# PRU_ICSS_PRU_CTRL register map
Vendor: Texas Instruments
Peripheral module from a debugger description file (folder am437x).
Registers are 32-bit, access per field, no defined reset value unless marked. A register's access mark holds for its fields unless they carry their own. Offsets are as the file gives them; lines under a group give offsets from that group; [hi:lo] are bit positions; {n}, {i} and the like mark numbered series; 'fields as' and 'values as' point back to an identical list; <NAME> marks a mode.

## PRU_ICSS_PRU_CTRL
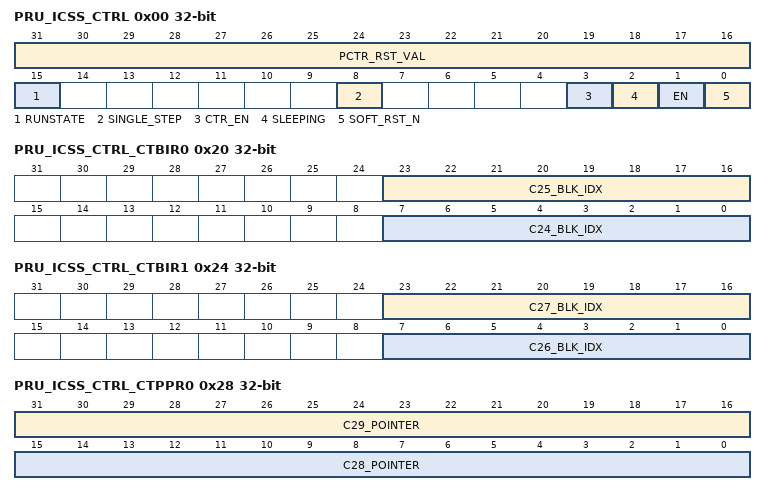
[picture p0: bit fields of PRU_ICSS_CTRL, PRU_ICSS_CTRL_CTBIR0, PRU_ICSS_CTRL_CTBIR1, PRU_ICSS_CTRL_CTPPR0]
0x00 PRU_ICSS_CTRL — CONTROL REGISTER
  [31:16] PCTR_RST_VAL rw — Program Counter Reset Value: This field controls the address where the PRU will start executing code from after it is taken out of reset.
  [15] RUNSTATE ro — Run State: This bit indicates whether the PRU is currently executing an instruction or is halted. This bit is used by an external debug agent to know when the PRU has actually halted when waiting for a HALT instruction to execute, a single step to finish, or any other time when the pru_enable has been cleared.
    1=en_2_0x1 (PRU is currently running and the host is locked out of the instruction RAM and debug registers regions.); 0=en_1_0x0 (PRU is halted and host has access to the instruction RAM and debug registers regions.)
  [8] SINGLE_STEP rw — Single Step Enable: This bit controls whether or not the PRU will only execute a single instruction when enabled. Note that this bit does not actually enable the PRU, it only sets the policy for how much code will be run after the PRU is enabled. The pru_enable bit must be explicitly asserted. It is legal to initialize both the SINGLE_STEP and EN bits simultaneously. (Two independent writes are not required to cause the stated functionality.)
    1=en_2_0x1 (PRU will execute a single instruction and then the pru_enable bit will be cleared.); 0=en_1_0x0 (PRU will free run when enabled.)
  [3] CTR_EN rw — PRU Cycle Counter Enable: Enables PRU cycle counters.
    1=en_2_0x1 (Counters enabled); 0=en_1_0x0 (Counters not enabled)
  [2] SLEEPING rw — PRU Sleep Indicator: This bit indicates whether or not the PRU is currently asleep.
    1=en_2_0x1 (PRU is asleep; If this bit is written to a 0, the PRU will be forced to power up from sleep mode.); 0=en_1_0x0 (PRU is not asleep)
  [1] EN rw — Processor Enable: This bit controls whether or not the PRU is allowed to fetch new instructions. If this bit is de-asserted while the PRU is currently running and has completed the initial cycle of a multi-cycle instruction (LBxO, SBxO, etc.), the current instruction will be allowed to complete before the PRU pauses execution. Otherwise, the PRU will halt immediately. Because of the unpredictability/timing sensitivity of the instruction execution loop, this bit is not a reliable indication of whether or not the PRU is currently running. The pru_state bit should be consulted for an absolute indication of the run state of the core. When the PRU is halted, its internal state remains coherent therefore this bit can be reasserted without issuing a software reset and the PRU will resume processing exactly where it left off in the instruction stream.
    1=en_2_0x1 (PRU is enabled.); 0=en_1_0x0 (PRU is disabled.)
  [0] SOFT_RST_N ro — Soft Reset: When this bit is cleared, the PRU will be reset. This bit is set back to 1 on the next cycle after it has been cleared.
0x04 PRU_ICSS_CTRL_STS ro — STATUS REGISTER
  [15:0] PCTR — Program Counter: This field is a registered (1 cycle delayed) reflection of the PRU program counter. Note that the PC is an instruction address where each instruction is a 32 bit word. This is not a byte address and to compute the byte address just multiply the PC by 4 (PC of 2 = byte address of 0x8, or PC of 8 = byte address of 0x20).
0x08 PRU_ICSS_CTRL_WAKEUP_EN rw — WAKEUP ENABLE REGISTER
  [31:0] BITWISE_ENS — Wakeup Enables: This field is ANDed with the incoming R31 status inputs (whose bit positions were specified in the stmap parameter) to produce a vector which is unary ORed to produce the status_wakeup source for the core. Setting any bit in this vector will allow the corresponding status input to wake up the core when it is asserted high. The PRU should set this enable vector prior to executing a SLP (sleep) instruction to ensure that the desired sources can wake up the core.
0x0C PRU_ICSS_CTRL_CYCLE access not given — CYCLE COUNT. This register counts the number of cycles for which the PRU has been enabled.
  [31:0] CYCLECOUNT — This value is incremented by 1 for every cycle during which the PRU is enabled and the counter is enabled (both bits EN and CTR_EN set in the PRU control register). Counting halts while the PRU is disabled or counter is disabled, and resumes when re-eneabled. Counter clears the CTR_EN bit in the PRU control register when the count reaches 0xFFFFFFFF. (Count does does not wrap). The register can be read at any time. The register can be cleared when the counter or PRU is disabled. Clearing this register also clears the PRU Stall Count Register.
0x10 PRU_ICSS_CTRL_STALL access not given — STALL COUNT. This register counts the number of cycles for which the PRU has been enabled, but unable to fetch a new instruction. It is linked to the Cycle Count Register (0x0C) such that this register reflects the stall cycles measured over the same cycles as counted by the cycle count register. Thus the value of this register is always less than or equal to cycle count.
  [31:0] STALLCOUNT — This value is incremented by 1 for every cycle during which the PRU is enabled and the counter is enabled (both bits EN and CTR_EN set in the PRU control register), and the PRU was unable to fetch a new instruction for any reason.
0x20 PRU_ICSS_CTRL_CTBIR0 — CONSTANT TABLE BLOCK INDEX REGISTER 0. This register is used to set the block indices which are used to modify entries 24 and 25 in the PRU Constant Table. This register can be written by the PRU whenever it needs to change to a new base pointer for a block in the State / Scratchpad RAM. This function is useful since the PRU is often processing multiple processing threads which require it to change contexts. The PRU can use this register to avoid requiring excessive amounts of code for repetitive context switching. The format of this register is as follows:
  [23:16] C25_BLK_IDX rw — PRU Constant Entry 25 Block Index: This field sets the value that will appear in bits 11 to 8 of entry 25 in the PRU Constant Table.
  [7:0] C24_BLK_IDX rw — PRU Constant Entry 24 Block Index: This field sets the value that will appear in bits 11 to 8 of entry 24 in the PRU Constant Table.
0x24 PRU_ICSS_CTRL_CTBIR1 — CONSTANT TABLE BLOCK INDEX REGISTER 1. This register is used to set the block indices which are used to modify entries 24 and 25 in the PRU Constant Table. This register can be written by the PRU whenever it needs to change to a new base pointer for a block in the State / Scratchpad RAM. This function is useful since the PRU is often processing multiple processing threads which require it to change contexts. The PRU can use this register to avoid requiring excessive amounts of code for repetitive context switching. The format of this register is as follows:
  [23:16] C27_BLK_IDX rw — PRU Constant Entry 27 Block Index: This field sets the value that will appear in bits 11 to 8 of entry 27 in the PRU Constant Table.
  [7:0] C26_BLK_IDX rw — PRU Constant Entry 26 Block Index: This field sets the value that will appear in bits 11 to 8 of entry 26 in the PRU Constant Table.
0x28 PRU_ICSS_CTRL_CTPPR0 rw — CONSTANT TABLE PROGRAMMABLE POINTER REGISTER 0. This register allows the PRU to set up the 256-byte page index for entries 28 and 29 in the PRU Constant Table which serve as general purpose pointers which can be configured to point to any locations inside the session router address map. This register is useful when the PRU needs to frequently access certain structures inside the session router address space whose locations are not hard coded such as tables in scratchpad memory. This register is formatted as follows:
  [31:16] C29_POINTER — PRU Constant Entry 29 Pointer: This field sets the value that will appear in bits 23 to 8 of entry 29 in the PRU Constant Table.
  [15:0] C28_POINTER — PRU Constant Entry 28 Pointer: This field sets the value that will appear in bits 23 to 8 of entry 28 in the PRU Constant Table.
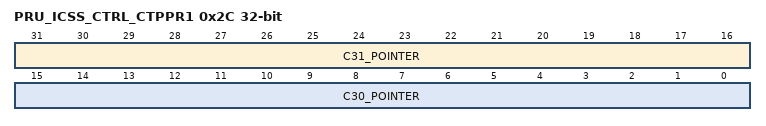
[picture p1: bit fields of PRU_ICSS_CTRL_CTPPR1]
0x2C PRU_ICSS_CTRL_CTPPR1 rw — CONSTANT TABLE PROGRAMMABLE POINTER REGISTER 1. This register functions the same as the PRU Constant Table Programmable Pointer Register 0 but allows the PRU to control entries 30 and 31 in the PRU Constant Table. This register is formatted as follows:
  [31:16] C31_POINTER — PRU Constant Entry 31 Pointer: This field sets the value that will appear in bits 23 to 8 of entry 31 in the PRU Constant Table.
  [15:0] C30_POINTER — PRU Constant Entry 30 Pointer: This field sets the value that will appear in bits 23 to 8 of entry 30 in the PRU Constant Table.
